# R7KA8P1AD register map
Vendor: Renesas Electronics Corporation; Series: RA8; File version: 1.10.02
CPU: CM85 r0p2, little endian, MPU, FPU, VTOR, 4 interrupt priority bits, 96 interrupts
Registers are 32-bit, read-write, reset 0x0 unless marked. A register's access mark holds for its fields unless they carry their own. Offsets are from the block's base; [hi:lo] are bit positions; {n}, {i} and the like mark numbered series; 'fields as' and 'values as' point back to an identical list.

## MIPI_DSI
Base 0x40346000
Same registers: MIPI_DSI_NS 0x50346000
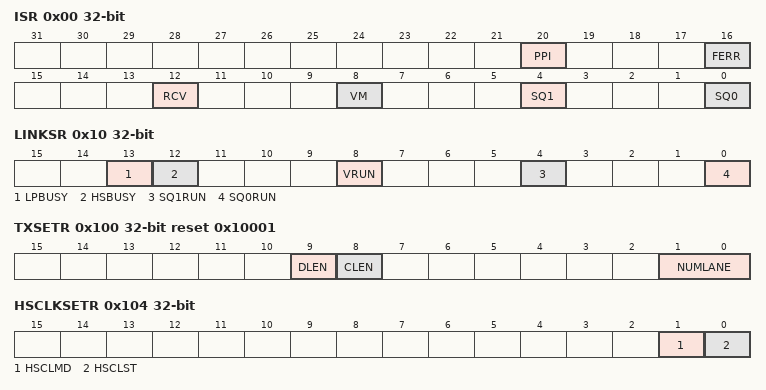
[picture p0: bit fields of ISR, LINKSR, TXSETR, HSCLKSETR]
0x00 ISR ro — Interrupt Status Register
  [20] PPI — PPI Interrupt Flag
    0=No interrupt detected; 1=PPI interrupt detected
  [16] FERR — Fatal Error Interrupt Flag
    0=No interrupt detected; 1=Fatal Error interrupt detected
  [12] RCV — Receive Interrupt Flag
    0=No interrupt detected; 1=Receive interrupt detected
  [8] VM — Video Mode Interrupt Flag
    0=No interrupt detected; 1=Video Mode interrupt detected
  [4] SQ1 — Sequence Channel-1 Interrupt Flag
    0=No interrupt detected; 1=Sequence Operation Channel-1 interrupt detected
  [0] SQ0 — Sequence Channel-0 Interrupt Flag
    0=No interrupt detected; 1=Sequence Operation Channel-0 interrupt detected
0x10 LINKSR ro — Link Status Register
  [13] LPBUSY — LP Operation Busy Flag
    0=LP mode stopped; 1=LP mode in operation
  [12] HSBUSY — HS Operation Busy Flag
    0=HS mode stopped; 1=HS mode in operation
  [8] VRUN — Video Mode Operation Running Flag
    0=Video mode stopped; 1=Video mode in operation
  [4] SQ1RUN — Sequence Channel-1 Running Flag
    0=Sequence Operation Channel-1 stopped; 1=Sequence Operation Channel-1 in operation
  [0] SQ0RUN — Sequence Channel-0 Running Flag
    0=Sequence Operation Channel-0 stopped; 1=Sequence Operation Channel-0 in operation
0x100 TXSETR reset 0x10001 — Transmit Set Register
  [9] DLEN — Data Lane Enable
    0=Disable; 1=Enable
  [8] CLEN — Clock Lane Enable
    0=Disable; 1=Enable
  [1:0] NUMLANE — Number of Lane
    0=1 Lane (Use of Lane-0); 1=2 Lane (Use of Lane-0 and Lane-1); other=Others (Setting prohibited)
0x104 HSCLKSETR — HS Clock Set Register
  [1] HSCLMD — HS Clock Running Mode
    0=Non-continuous clock mode; 1=Continuous clock mode
  [0] HSCLST — HS Clock Start
    0=Stop HS transmission (keep LP state); 1=Start HS transmission
0x108 ULPSSETR reset 0xA0 — ULPS Set Register
  [7:0] WKUP — ULPS Wakeup Period
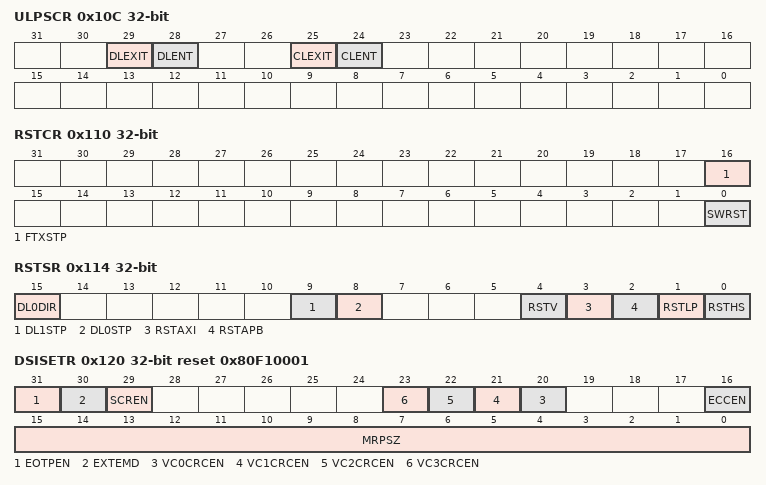
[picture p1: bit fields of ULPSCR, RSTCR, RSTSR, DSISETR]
0x10C ULPSCR wo — ULPS Control Register
  [29] DLEXIT — DL ULPS Exit
    0=No operation; 1=Data Lanes exit from ULPS
  [28] DLENT — DL ULPS Enter
    0=No operation; 1=Transition Data Lanes to ULPS
  [25] CLEXIT — CL ULPS Exit
    0=No operation; 1=Clock Lane exits from ULPS
  [24] CLENT — CL ULPS Enter
    0=No operation; 1=Transition Clock Lane to ULPS
0x110 RSTCR — Reset Control Register
  [16] FTXSTP — Force TX Stop Mode
    0=Finish the Force Stop state; 1=Force data lanes into transmit mode and generate Stop state
  [0] SWRST — Software Reset
    0=Complete the software reset; 1=Request a software reset
0x114 RSTSR ro — Reset Status Register
  [15] DL0DIR — Data Lane-0 Direction
    0=TX mode; 1=RX mode
  [9] DL1STP — Data Lane-1 Stop Status
    0=Not Stop state; 1=Stop state
  [8] DL0STP — Data Lane-0 Stop Status
    0=Not Stop state; 1=Stop state
  [4] RSTV — Video Software Reset Status
    0=Not in software reset procedure; 1=Running software reset procedure for Video mode
  [3] RSTAXI — AXI Software Reset Status
    0=Not in software reset procedure; 1=Running software reset procedure for AXI bus
  [2] RSTAPB — APB Software Reset Status
    0=Not in software reset procedure; 1=Running software reset procedure for APB bus
  [1] RSTLP — LP Software Reset Status
    0=Not in software reset procedure; 1=Running software reset procedure for LP mode
  [0] RSTHS — HS Software Reset Status
    0=Not in software reset procedure; 1=Running software reset procedure for HS mode
0x120 DSISETR reset 0x80F10001 — DSI Set Register
  [31] EOTPEN — HS Transfer EoTp Enable
    0=Disable; 1=Enable
  [30] EXTEMD — External Tearing Effect Detection Sense Select
    0=Rising edge; 1=Falling edge
  [29] SCREN — Data Scramble Enable
    0=Disable; 1=Enable
  [n+20] VC{n}CRCEN (n=0..3) — VC-{n} CRC Check Enable
    0=Disable; 1=Enable
  [16] ECCEN — ECC Check Enable
    0=Disable; 1=Enable
  [15:0] MRPSZ — Maximum Return Packet Size
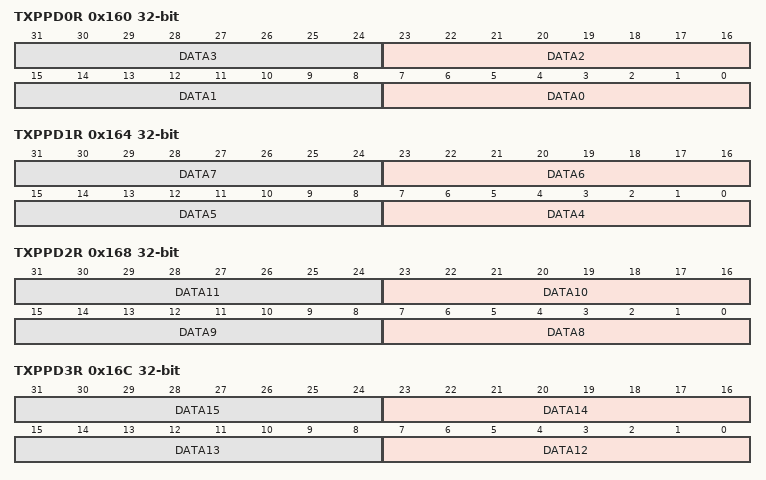
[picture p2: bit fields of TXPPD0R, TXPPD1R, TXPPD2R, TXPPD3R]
0x160 TXPPD0R — Transmit Packet Payload Data 0 Register
  [8n+7:8n] DATA{n} (n=0..3) — Payload Data {n}
0x164 TXPPD1R — Transmit Packet Payload Data 1 Register
  [8n-25:8n-32] DATA{n} (n=4..7) — Payload Data {n}
0x168 TXPPD2R — Transmit Packet Payload Data 2 Register
  [8n-57:8n-64] DATA{n} (n=8..11) — Payload Data {n}
0x16C TXPPD3R — Transmit Packet Payload Data 3 Register
  [8n-89:8n-96] DATA{n} (n=12..15) — Payload Data {n}
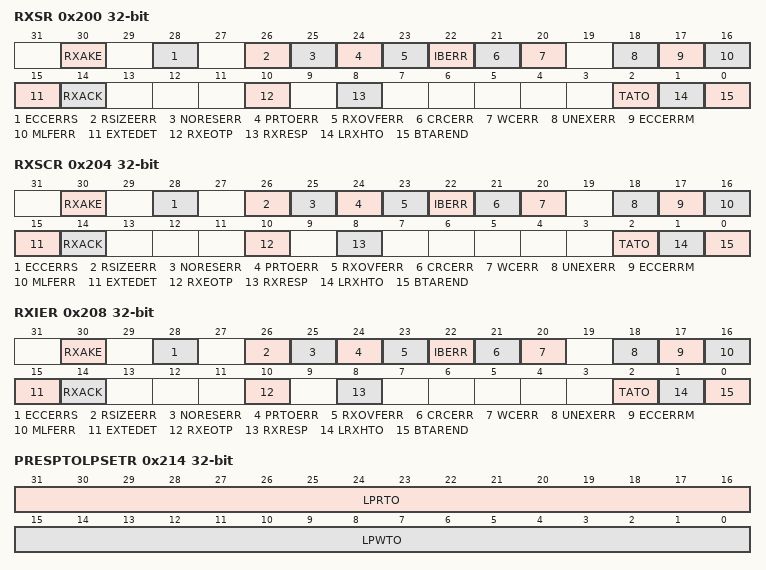
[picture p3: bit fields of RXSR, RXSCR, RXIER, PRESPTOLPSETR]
0x200 RXSR ro — Receive Status Register
  [30] RXAKE — Acknowledge and Error Report Receive Interrupt Flag
    0=No received; 1=An acknowledge and error report packet received
  [28] ECCERRS — Single Bit ECC Error Interrupt Flag
    0=No error detected; 1=A single-bit ECC error detected
  [26] RSIZEERR — Return Packet Size Error Interrupt Flag
    0=No error detected; 1=Oversize error in a received long packet detected
  [25] NORESERR — No Response Error Interrupt Flag
    0=No error occurred; 1=No triggers or packets returned during BTA period
  [24] PRTOERR — Peripheral Response Timeout Error Interrupt Flag
    0=No error occurred; 1=Peripheral response timeout occurred
  [23] RXOVFERR — Receive Buffer Overflow Error Interrupt Flag
    0=No error detected; 1=A buffer overflow error detected on receiving long packets
  [22] IBERR — Internal Bus Error Interrupt Flag
    0=No error detected; 1=Internal AXI bus write failed
  [21] CRCERR — CRC Error Interrupt Flag
    0=No error detected; 1=CRC error detected
  [20] WCERR — Word Count Error Interrupt Flag
    0=No error detected; 1=The length of the received packet is shorter than the Word Count (WC) indicated in the packet header
  [18] UNEXERR — Unexpected Packet Error Interrupt Flag
    0=No error; 1=Unexpected packet received
  [17] ECCERRM — Multi Bit ECC Error Interrupt Flag
    0=No error detected; 1=A multi-bit ECC error detected
  [16] MLFERR — Malform Error Interrupt Flag
    0=No error received; 1=A packet of less than 4 bytes received
  [15] EXTEDET — External Tearing Effect Detect Interrupt Flag
    0=Not detected; 1=External tearing effect detected
  [14] RXACK — ACK Trigger Receive Interrupt Flag
    0=No trigger received; 1=ACK trigger received
  [10] RXEOTP — EoTp Receive Interrupt Flag
    0=No received; 1=EoTp received
  [8] RXRESP — Response Packet Receive Interrupt Flag
    0=No response received; 1=Response packet received
  [2] TATO — Turnaround Acknowledge Timeout Interrupt Flag
    0=Not detected; 1=Turnaround Acknowledge Timeout (TA_TO) detected
  [1] LRXHTO — LP-RX Host Processor Timeout Interrupt Flag
    0=Not detected; 1=LP-RX Host Processor Timeout (LRX-H_TO) detected
  [0] BTAREND — BTA Request End Interrupt Flag
    0=Not detected; 1=BTA completion detected
0x204 RXSCR wo — Receive Status Clear Register
  [30] RXAKE — Acknowledge and Error Report Receive Interrupt Flag Clear
    0=No operation; 1=Clear the RXSR.RXAKE flag
  [28] ECCERRS — Single Bit ECC Error Interrupt Flag Clear
    0=No operation; 1=Clear the RXSR.ECCERRS flag
  [26] RSIZEERR — Return Packet Size Error Interrupt Flag Clear
    0=No operation; 1=Clear the RXSR.RSIZEERR flag
  [25] NORESERR — No Response Error Interrupt Flag Clear
    0=No operation; 1=Clear the RXSR.NORESERR flag
  [24] PRTOERR — Peripheral Response Timeout Error Interrupt Flag Clear
    0=No operation; 1=Clear the RXSR.PRTOERR flag
  [23] RXOVFERR — Receive Buffer Overflow Error Interrupt Flag Clear
    0=No operation; 1=Clear the RXSR.RXOVFERR flag
  [22] IBERR — Internal Bus Error Interrupt Flag Clear
    0=No operation; 1=Clear the RXSR.IBERR flag
  [21] CRCERR — CRC Error Interrupt Flag Clear
    0=No operation; 1=Clear the RXSR.CRCERR flag
  [20] WCERR — Word Count Error Interrupt Flag Clear
    0=No operation; 1=Clear the RXSR.WCERR flag
  [18] UNEXERR — Unexpected Packet Error Interrupt Flag Clear
    0=No operation; 1=Clear the RXSR.UNEXERR flag
  [17] ECCERRM — Multi Bit ECC Error Interrupt Flag Clear
    0=No operation; 1=Clear the RXSR.ECCERRM flag
  [16] MLFERR — Malform Error Interrupt Flag Clear
    0=No operation; 1=Clear the RXSR.MLFERR flag
  [15] EXTEDET — External Tearing Effect Detect Interrupt Flag Clear
    0=No operation; 1=Clear the RXSR.EXTEDET flag
  [14] RXACK — ACK Trigger Receive Interrupt Flag Clear
    0=No operation; 1=Clear the RXSR.RXACK flag
  [10] RXEOTP — EoTp Receive Interrupt Flag Clear
    0=No operation; 1=Clear the RXSR.RXEOTP flag
  [8] RXRESP — Response Packet Receive Interrupt Flag Clear
    0=No operation; 1=Clear the RXSR.RXRESP flag
  [2] TATO — Turnaround Acknowledge Timeout Interrupt Flag Clear
    0=No operation; 1=Clear the RXSR.TATO flag
  [1] LRXHTO — LP-RX Host Processor Timeout Interrupt Flag Clear
    0=No operation; 1=Clear the RXSR.LRXHTO flag
  [0] BTAREND — BTA Request End Interrupt Flag Clear
    0=No operation; 1=Clear the RXSR.BTAREND flag
0x208 RXIER — Receive Interrupt Enable Register
  [all] fields
    0=Disable; 1=Enable
  [30] RXAKE — Acknowledge and Error Report Receive Interrupt Enable
  [28] ECCERRS — Single Bit ECC Error Interrupt Enable
  [26] RSIZEERR — Return Packet Size Error Interrupt Enable
  [25] NORESERR — No Response Error Interrupt Enable
  [24] PRTOERR — Peripheral Response Timeout Error Interrupt Enable
  [23] RXOVFERR — Receive Buffer Overflow Error Interrupt Enable
  [22] IBERR — Internal Bus Error Interrupt Enable
  [21] CRCERR — CRC Error Interrupt Enable
  [20] WCERR — Word Count Error Interrupt Enable
  [18] UNEXERR — Unexpected Packet Error Interrupt Enable
  [17] ECCERRM — Multi-bit ECC Error Interrupt Enable
  [16] MLFERR — Malform Error Interrupt Enable
  [15] EXTEDET — External Tearing Effect Detect Interrupt Enable
  [14] RXACK — ACK Trigger Receive Interrupt Enable
  [10] RXEOTP — EoTp Receive Interrupt Enable
  [8] RXRESP — Response Packet Receive Interrupt Enable
  [2] TATO — Turnaround Acknowledge Timeout Interrupt Enable
  [1] LRXHTO — LP-RX Host Processor Timeout Interrupt Enable
  [0] BTAREND — BTA Request End Interrupt Enable
0x210 PRESPTOBTASETR — Peripheral Response Timeout BTA Set Register
  [31:0] PRTBTA — Peripheral Response Timeout Count
0x214 PRESPTOLPSETR — Peripheral Response Timeout LP Set Register
  [31:16] LPRTO — LPDT READ Request Timeout
  [15:0] LPWTO — LPDT WRITE Request Timeout
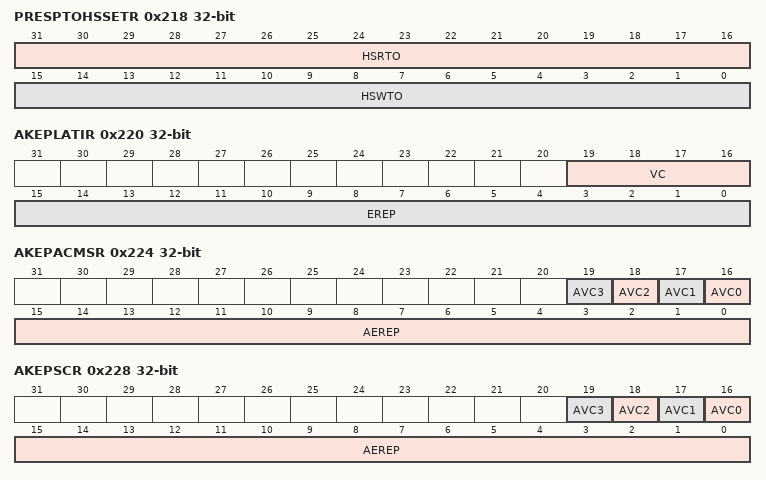
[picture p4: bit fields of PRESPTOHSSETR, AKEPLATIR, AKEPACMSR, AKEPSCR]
0x218 PRESPTOHSSETR — Peripheral Response Timeout HS Set Register
  [31:16] HSRTO — HS READ Request Timeout
  [15:0] HSWTO — HS WRITE Request Timeout
0x220 AKEPLATIR ro — Acknowledge and Error Report Packet Parameter Latest Info Register
  [19:16] VC — Virtual Channel ID
    0=No Error Report received; 1=From VC-0; 2=From VC-1; 4=From VC-2; 8=From VC-3; other=Others (Reserved)
  [15:0] EREP — Error Report
0x224 AKEPACMSR ro — Acknowledge and Error Report Packet Parameter Accumulate Status Register
  [n+16] AVC{n} (n=0..3) — Virtual Channel-{n} Accumulated Information
    0=No Error Report received from VC-{n}; 1=Received an Acknowledge and Error Report from VC-{n}
  [15:0] AEREP — Accumulated Error Report
0x228 AKEPSCR wo — Acknowledge and Error Report Packet Parameter Status Clear Register
  [n+16] AVC{n} (n=0..3) — Virtual Channel-{n} Accumulated Information Clear
    0=No operation; 1=Clear the AKEPACMSR.AVC{n} bit
  [15:0] AEREP — Accumulated Error Report Clear
    0=No operation; 1=Clear the AKEPACMSR.AEREP[15:0] bits
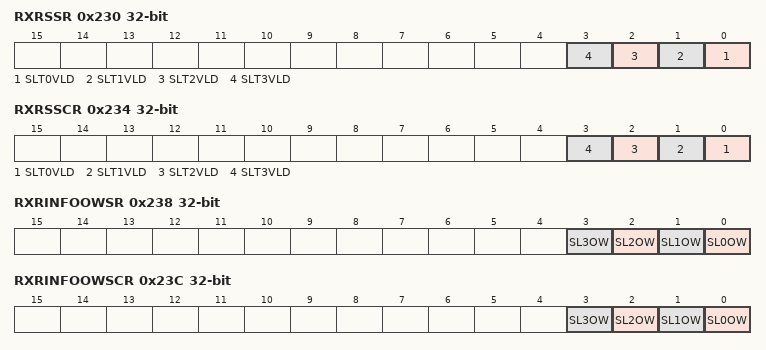
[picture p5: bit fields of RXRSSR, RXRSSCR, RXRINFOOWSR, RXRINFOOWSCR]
0x230 RXRSSR ro — Receive Result Saved Status Register
  [n] SLT{n}VLD (n=0..3) — Slot-{n} Valid Flag
    0=None received; 1=Response packet is received and stored in the RXRSS{n}R register
0x234 RXRSSCR wo — Receive Result Saved Status Clear Register
  [n] SLT{n}VLD (n=0..3) — Slot-{n} Valid Flag Clear
    0=No operation; 1=Clear the RXRSSR.SLT{n}VLD flag
0x238 RXRINFOOWSR ro — Receive Result Info Overwrite Status Register
  [n] SL{n}OW (n=0..3) — Slot-{n} Information Overwrite Flag
    0=No overwritten; 1=Slot-{n} information overwritten
0x23C RXRINFOOWSCR wo — Receive Result Info Overwrite Status Clear Register
  [n] SL{n}OW (n=0..3) — Slot-{n} Information Overwrite Flag Clear
    0=No operation; 1=Clear the RXRINFOOWSR.SL{n}OW flag
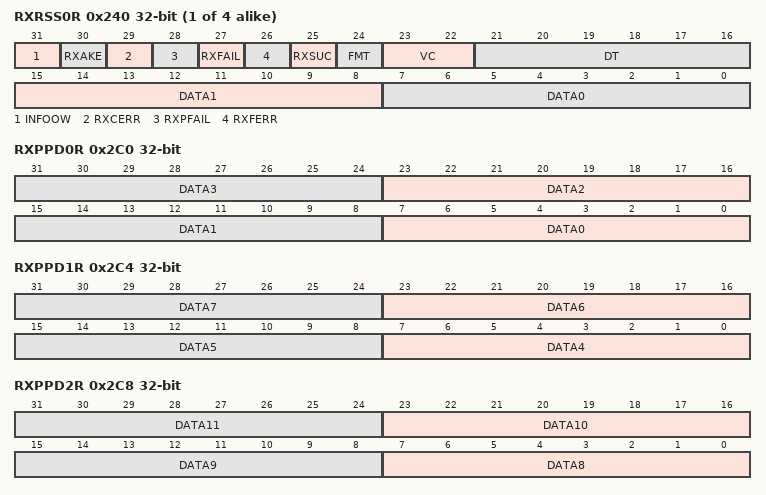
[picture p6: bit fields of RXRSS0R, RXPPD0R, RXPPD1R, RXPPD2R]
{0x240+4i} RXRSS{i}R (i=0..3) ro — Receive Result Save Slot-x Register (x = 0 to 3)
  [31] INFOOW — Information Overwrite
    0=No update; 1=This register information (RXRSSxR[30:0]) was overwritten
  [30] RXAKE — Receive Acknowledge and Error Report Packet
    0=No received; 1=An Acknowledge and Error Report packet received
  [29] RXCERR — Receive Correctable Error
    0=No error; 1=Correctable error detected
  [28] RXPFAIL — Receive Packet Data Fail
    0=No error; 1=Payload data not saved correctly
  [27] RXFAIL — Receive Fail
    0=No error; 1=Expected receive did not occur
  [26] RXFERR — Fatal Error
    0=No fatal error; 1=Fatal timeout occurred during BTA
  [25] RXSUC — Receive Success
    0=No received; 1=Response packet or ACK trigger received
  [24] FMT — Packet Format
    0=Short packet; 1=Long packet
  [23:22] VC — Virtual Channel ID
  [21:16] DT — Data Type
  [15:8] DATA1
  [7:0] DATA0
0x2C0 RXPPD0R ro — Receive Packet Payload Data 0 Register
  [8n+7:8n] DATA{n} (n=0..3) — Payload Data {n}
0x2C4 RXPPD1R ro — Receive Packet Payload Data 1 Register
  [8n-25:8n-32] DATA{n} (n=4..7) — Payload Data {n}
0x2C8 RXPPD2R ro — Receive Packet Payload Data 2 Register
  [8n-57:8n-64] DATA{n} (n=8..11) — Payload Data {n}
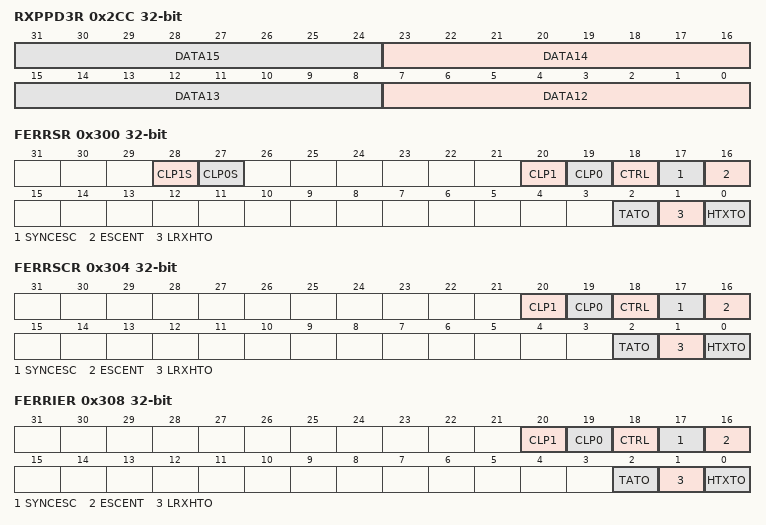
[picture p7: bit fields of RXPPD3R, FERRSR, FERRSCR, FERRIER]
0x2CC RXPPD3R ro — Receive Packet Payload Data 3 Register
  [8n-89:8n-96] DATA{n} (n=12..15) — Payload Data {n}
0x2E0 HSTXTOSETR — HS TX Timeout Set Register
  [31:0] HTXTO — HS TX Timeout Count
0x2E4 LRXHTOSETR — LRX-H Timeout Set Register
  [31:0] LRXHTO — LP-RX Host Processor Timeout
0x2E8 TATOSETR — TA Timeout Set Register
  [31:0] TATO — Turnaround Acknowledge Timeout
0x300 FERRSR ro — Fatal Error Status Register
  [28] CLP1S — LP1 Contention Error Status
    0=Normal state; 1=LP1 Contention Error (ErrContentionLP1) state
  [27] CLP0S — LP0 Contention Error Status
    0=Normal state; 1=LP0 Contention Error (ErrContentionLP0) state
  [20] CLP1 — LP1 Contention Error Interrupt Flag
    0=No error detected; 1=LP1 Contention Error (ErrContentionLP1) detected
  [19] CLP0 — LP0 Contention Error Interrupt Flag
    0=No error detected; 1=LP0 Contention Error (ErrContentionLP0) detected
  [18] CTRL — Control Error Interrupt Flag
    0=No error detected; 1=Control Error (ErrControl) detected
  [17] SYNCESC — LPDT Sync Error Interrupt Flag
    0=No error detected; 1=LPDT Synchronization Error (ErrSyncEsc) detected
  [16] ESCENT — Escape mode Entry Error Interrupt Flag
    0=No error detected; 1=Escape mode Entry Error (ErrEsc) detected
  [2] TATO — Turnaround Acknowledge Timeout Interrupt Flag
    values as RXSR.TATO
  [1] LRXHTO — LP-RX Host Processor Timeout Interrupt Flag
    values as RXSR.LRXHTO
  [0] HTXTO — HS TX Timeout Interrupt Flag
    0=Not detected; 1=HS TX Timeout (HTX_TO) detected
0x304 FERRSCR wo — Fatal Error Status Clear Register
  [20] CLP1 — LP1 Contention Error Interrupt Flag Clear
    0=No operation; 1=Clear the FERRSR.CLP1 flag
  [19] CLP0 — LP0 Contention Error Interrupt Flag Clear
    0=No operation; 1=Clear the FERRSR.CLP0 flag
  [18] CTRL — Control Error Interrupt Flag Clear
    0=No operation; 1=Clear the FERRSR.CTRL flag
  [17] SYNCESC — LPDT Sync Error Interrupt Flag Clear
    0=No operation; 1=Clear the FERRSR.SYNCESC flag
  [16] ESCENT — Escape Mode Entry Error Interrupt Flag Clear
    0=No operation; 1=Clear the FERRSR.ESCENT flag
  [2] TATO — Turnaround Acknowledge Timeout Interrupt Flag Clear
    0=No operation; 1=Clear the FERRSR.TATO flag
  [1] LRXHTO — LP-RX Host Processor Timeout Interrupt Flag Clear
    0=No operation; 1=Clear the FERRSR.LRXHTO flag
  [0] HTXTO — HS TX Timeout Interrupt Flag Clear
    0=No operation; 1=Clear the FERRSR.HTXTO flag
0x308 FERRIER — Fatal Error Interrupt Enable Register
  [all] fields
    0=Disable; 1=Enable
  [20] CLP1 — LP1 Contention Error Interrupt Enable
  [19] CLP0 — LP0 Contention Error Interrupt Enable
  [18] CTRL — Control Error Interrupt Enable
  [17] SYNCESC — LPDT Sync Error Interrupt Enable
  [16] ESCENT — Escape mode Entry Error Interrupt Enable
  [2] TATO — Turnaround Acknowledge Timeout Interrupt Enable
  [1] LRXHTO — LP-RX Host Processor Timeout Interrupt Enable
  [0] HTXTO — HS TX Timeout Interrupt Enable
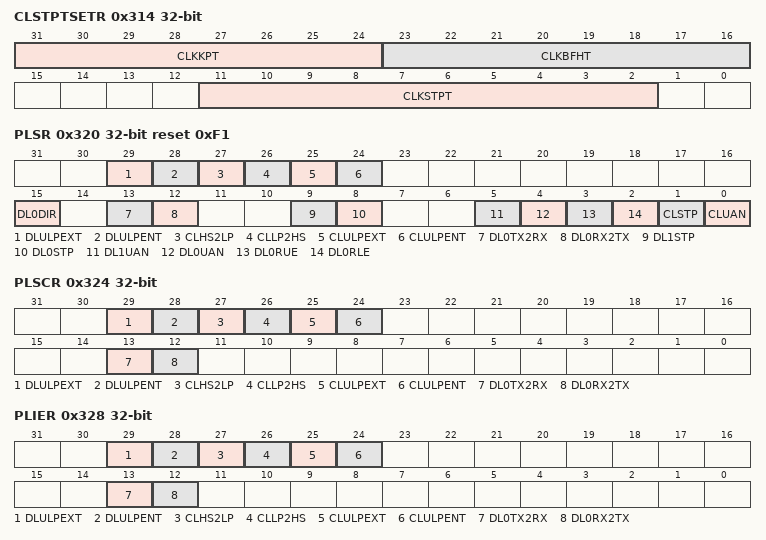
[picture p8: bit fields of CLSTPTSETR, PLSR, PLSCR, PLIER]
0x314 CLSTPTSETR — Clock Lane Stop Time Set Register
  [31:24] CLKKPT — Clock Keep Time
  [23:16] CLKBFHT — Clock Beforehand Time
  [11:2] CLKSTPT — Clock Stop Time
0x318 LPTRNSTSETR — LP Transition Time Set Register
  [9:0] GOLPBKT — Go LP and Back Time
0x320 PLSR ro reset 0xF1 — Physical Lane Status Register
  [29] DLULPEXT — Data Lane ULPS Exit Interrupt Flag
    0=Not detected; 1=Detected
  [28] DLULPENT — Data Lane ULPS Enter Interrupt Flag
    0=Not detected; 1=Detected
  [27] CLHS2LP — Clock Lane HS to LP Transition Interrupt Flag
    0=Not detected; 1=Detected
  [26] CLLP2HS — Clock Lane LP to HS Transition Interrupt Flag
    0=Not detected; 1=Detected
  [25] CLULPEXT — Clock Lane ULPS Exit Interrupt Flag
    0=Not detected; 1=Detected
  [24] CLULPENT — Clock Lane ULPS Enter Interrupt Flag
    0=Not detected; 1=Detected
  [15] DL0DIR — Data Lane-0 Direction
    0=Transmitter; 1=Receiver
  [13] DL0TX2RX — Data Lane-0 TX to RX Transition Interrupt Flag
    0=Not detected; 1=Detected
  [12] DL0RX2TX — Data Lane-0 RX to TX Transition Interrupt Flag
    0=Not detected; 1=Detected
  [9] DL1STP — Data Lane-1 Stop Status
    0=Not in Stop state; 1=In Stop state
  [8] DL0STP — Data Lane-0 Stop Status
    0=Not in Stop state; 1=In Stop state
  [5] DL1UAN — Data Lane-1 UlpsActiveNot Status
    0=In ULP state; 1=Not in ULP state
  [4] DL0UAN — Data Lane-0 UlpsActiveNot Status
    0=In ULP state; 1=Not in ULP state
  [3] DL0RUE — Data Lane-0 RxUlpsEsc Status
    0=Not in Escape Ultra-Low Power (Receive) mode; 1=In Escape Ultra-Low Power (Receive) mode
  [2] DL0RLE — Data Lane-0 RxLpdtEsc Status
    0=Not in Escape Low-Power Data Receive mode; 1=In Escape Low-Power Data Receive mode
  [1] CLSTP — Clock Lane Stop Status
    0=Not in Stop state; 1=In Stop state
  [0] CLUAN — Clock Lane UlpsActiveNot Status
    0=In ULP state; 1=Not in ULP state
0x324 PLSCR wo — Physical Lane Status Clear Register
  [29] DLULPEXT — Data Lane ULPS Exit Interrupt Flag Clear
    0=No operation; 1=Clear the PLSR.DLULPEXT flag
  [28] DLULPENT — Data Lane ULPS Enter Interrupt Flag Clear
    0=No operation; 1=Clear the PLSR.DLULPENT flag
  [27] CLHS2LP — Clock Lane HS to LP Transition Interrupt Flag Clear
    0=No operation; 1=Clear the PLSR.CLHS2LP flag
  [26] CLLP2HS — Clock Lane LP to HS Transition Interrupt Flag Clear
    0=No operation; 1=Clear the PLSR.CLLP2HS flag
  [25] CLULPEXT — Clock Lane ULPS Exit Interrupt Flag Clear
    0=No operation; 1=Clear the PLSR.CLULPEXT flag
  [24] CLULPENT — Clock Lane ULPS Enter Interrupt Flag Clear
    0=No operation; 1=Clear the PLSR.CLULPENT flag
  [13] DL0TX2RX — Data Lane-0 TX to RX Transition Interrupt Flag Clear
    0=No operation; 1=Clear the PLSR.DL0TX2RX flag
  [12] DL0RX2TX — Data Lane-0 RX to TX Transition Interrupt Flag Clear
    0=No operation; 1=Clear the PLSR.DL0RX2TX flag
0x328 PLIER — Physical Lane Interrupt Enable Register
  [all] fields
    0=Disable; 1=Enable
  [29] DLULPEXT — Data Lane ULPS Exit Interrupt Enable
  [28] DLULPENT — Data Lane ULPS Enter Interrupt Enable
  [27] CLHS2LP — Clock Lane HS to LP Transition Interrupt Enable
  [26] CLLP2HS — Clock Lane LP to HS Transition Interrupt Enable
  [25] CLULPEXT — Clock Lane ULPS Exit Interrupt Enable
  [24] CLULPENT — Clock Lane ULPS Enter Interrupt Enable
  [13] DL0TX2RX — Data Lane-0 TX to RX Transition Interrupt Enable
  [12] DL0RX2TX — Data Lane-0 RX to TX Transition Interrupt Enable
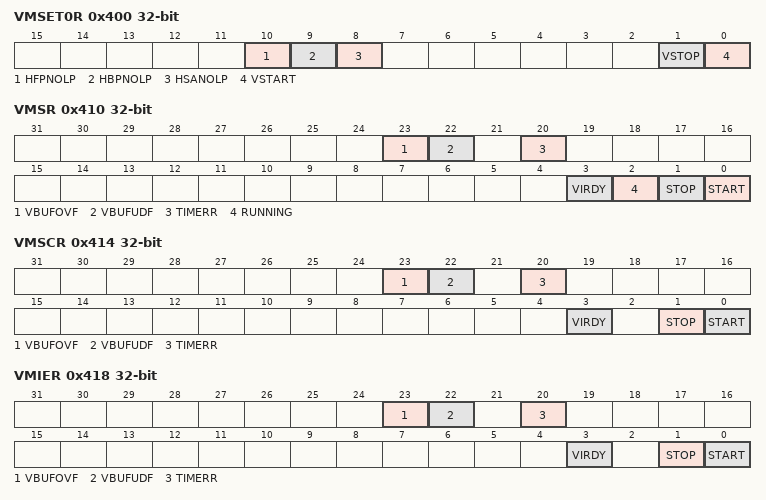
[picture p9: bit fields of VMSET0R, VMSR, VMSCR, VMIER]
0x400 VMSET0R — Video Mode Set 0 Register
  [10] HFPNOLP — HFP Period No LP
    0=Not suppressing the transition to LP during the HFP period; 1=Suppress the transition to LP during the HFP period and keep HS
  [9] HBPNOLP — HBP Period No LP
    0=Not suppressing the transition to LP during the HBP period; 1=Suppress the transition to LP during the HBP period and keep HS
  [8] HSANOLP — HSA Period No LP
    0=Not suppressing the transition to LP during the HSA period; 1=Suppress the transition to LP during the HSA period and keep HS
  [1] VSTOP wo — Video Mode Operation Stop
    0=No operation; 1=Stop Video mode operation
  [0] VSTART wo — Video Mode Operation Start
    0=No operation; 1=Start Video mode operation
0x404 VMSET1R reset 0x10530000 — Video Mode Set 1 Register
  [13:2] DLY — Delay Value
0x410 VMSR ro — Video Mode Status Register
  [23] VBUFOVF — Video Buffer Overflow Error Interrupt Flag
    0=Data overflow has not occurred; 1=Data overflow has occurred in the video buffer
  [22] VBUFUDF — Video Buffer Underflow Error Interrupt Flag
    0=Data underflow has not occurred; 1=Data underflow has occurred in the video buffer
  [20] TIMERR — Timing Error Interrupt Flag
    0=Timing error has not occurred; 1=Timing error has occurred during the Video mode operation
  [3] VIRDY — Video Mode Operation Ready Interrupt Flag
    0=Video mode operation is not ready; 1=Video mode operation is ready
  [2] RUNNING — Video Mode Operation Running Status
    0=Video mode operation is stopped; 1=Video mode operation is running
  [1] STOP — Video Mode Operation Stop Interrupt Flag
    0=Video mode operation has not stopped; 1=Video mode operation has stopped
  [0] START — Video Mode Operation Start Interrupt Flag
    0=Video mode operation has not started; 1=Video mode operation has started
0x414 VMSCR wo — Video Mode Status Clear Register
  [23] VBUFOVF — Video Buffer Overflow Error Interrupt Flag Clear
    0=No operation; 1=Clear the VMSR.VBUFOVF flag
  [22] VBUFUDF — Video Buffer Underflow Error Interrupt Flag Clear
    0=No operation; 1=Clear the VMSR.VBUFUDF flag
  [20] TIMERR — Timing Error Interrupt Flag Clear
    0=No operation; 1=Clear the VMSR.TIMERR flag
  [3] VIRDY — Video Mode Operation Ready Interrupt Flag Clear
    0=No operation; 1=Clear the VMSR.VIRDY flag
  [1] STOP — Video Mode Operation Stop Interrupt Flag Clear
    0=No operation; 1=Clear the VMSR.STOP flag
  [0] START — Video Mode Operation Start Interrupt Flag Clear
    0=No operation; 1=Clear the VMSR.START flag
0x418 VMIER — Video Mode Interrupt Enable Register
  [all] fields
    0=Disable; 1=Enable
  [23] VBUFOVF — Video Buffer Overflow Error Interrupt Enable
  [22] VBUFUDF — Video Buffer Underflow Error Interrupt Enable
  [20] TIMERR — Timing Error Interrupt Enable
  [3] VIRDY — Video Mode Operation Ready Interrupt Enable
  [1] STOP — Video Mode Operation Stop Interrupt Enable
  [0] START — Video Mode Operation Start Interrupt Enable
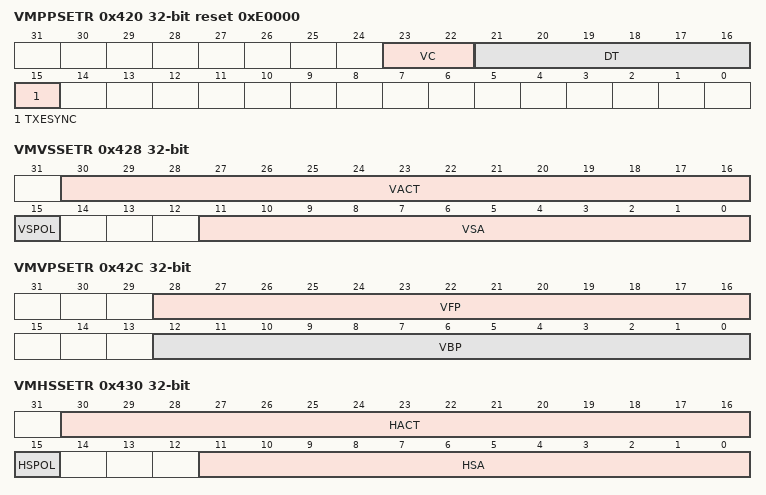
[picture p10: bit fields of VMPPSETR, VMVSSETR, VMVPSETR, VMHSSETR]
0x420 VMPPSETR reset 0xE0000 — Video Mode Pixel Packet Set Register
  [23:22] VC — Video Mode Virtual Channel
  [21:16] DT — Video Mode Data Type
    14=Packed Pixel Stream, 16-bit RGB; 30=Packed Pixel Stream, 18-bit RGB; 62=Packed Pixel Stream, 24-bit RGB; other=Others (Setting prohibited)
  [15] TXESYNC — Transmit End of Sync Pulse
    0=HSE and VSE are not transmitted; 1=HSE and VSE are transmitted
0x428 VMVSSETR — Video Mode Vertical Size Set Register
  [30:16] VACT — Vertical Active Lines
  [15] VSPOL — VSYNC Polarity
    0=Active-high; 1=Active-low
  [11:0] VSA — VSA Lines
0x42C VMVPSETR — Video Mode Vertical Porch Set Register
  [28:16] VFP — VFP Lines
  [12:0] VBP — VBP Lines
0x430 VMHSSETR — Video Mode Horizontal Size Set Register
  [30:16] HACT — HACT Pixels
  [15] HSPOL — HSYNC Polarity
    0=Active-high; 1=Active-low
  [11:0] HSA — HSA Pixels
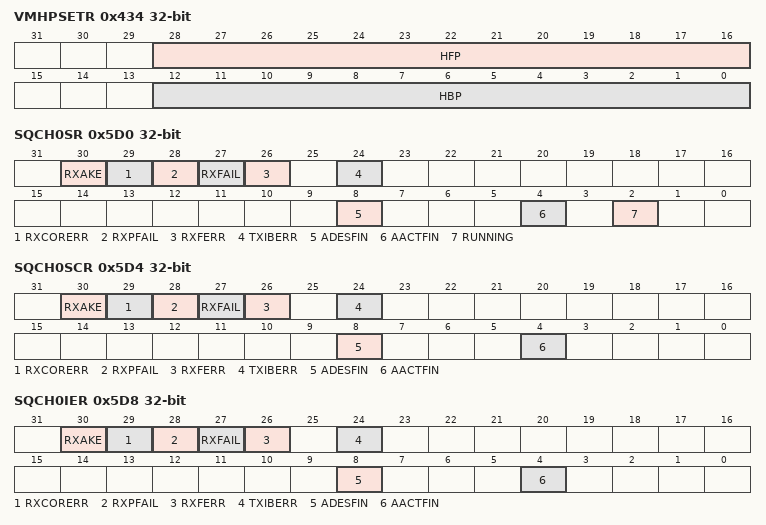
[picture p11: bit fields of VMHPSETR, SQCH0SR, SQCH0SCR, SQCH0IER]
0x434 VMHPSETR — Video Mode Horizontal Porch Set Register
  [28:16] HFP — HFP Pixels
  [12:0] HBP — HBP Pixels
0x5C0 SQCH0SET0R wo reset 0x800000 — Sequence Channel 0 Set 0 Register
  [0] START — Sequence Operation Start
    0=No operation; 1=Start the sequence operation
0x5D0 SQCH0SR ro — Sequence Channel 0 Status Register
  [30] RXAKE — Receive Acknowledge and Error Report Packet Interrupt Flag
    0=No error; 1=Acknowledge and Error Report Packet is received
  [29] RXCORERR — Receive Correctable Error Interrupt Flag
    0=No error; 1=Received packets have a correctable error
  [28] RXPFAIL — Receive Packet Data Fail Interrupt Flag
    0=No error; 1=Received packet data is not stored correctly
  [27] RXFAIL — Receive Fail Interrupt Flag
    0=No error; 1=Expected receive did not take place
  [26] RXFERR — Receive Fatal Error Interrupt Flag
    0=No error; 1=Fatal timeout occurred during BTA
  [24] TXIBERR — TX Internal Bus Error Interrupt Flag
    0=No error; 1=Internal AXI bus read error occurred
  [8] ADESFIN — All Descriptors Finish Interrupt Flag
    0=All descriptors have not finished; 1=All descriptors finished operations
  [4] AACTFIN — All Actions Finish Interrupt Flag
    0=All actions of a descriptor have not finished; 1=All actions of a descriptor finished operations
  [2] RUNNING — Sequence Operation Running Status
    0=Sequence operation is stopped; 1=Sequence operation is running
0x5D4 SQCH0SCR wo — Sequence Channel 0 Status Clear Register
  [30] RXAKE — Receive Acknowledge and Error Report Packet Interrupt Flag Clear
    0=No operation; 1=Clear the SQCH0SR.RXAKE flag
  [29] RXCORERR — Receive Correctable Error Interrupt Flag Clear
    0=No operation; 1=Clear the SQCH0SR.RXCORERR flag
  [28] RXPFAIL — Receive Packet Data Fail Interrupt Flag Clear
    0=No operation; 1=Clear the SQCH0SR.RXPFAIL flag
  [27] RXFAIL — Receive Fail Interrupt Flag Clear
    0=No operation; 1=Clear the SQCH0SR.RXFAIL flag
  [26] RXFERR — Receive Fatal Error Interrupt Flag Clear
    0=No operation; 1=Clear the SQCH0SR.RXFERR flag
  [24] TXIBERR — TX Internal Bus Error Interrupt Flag Clear
    0=No operation; 1=Clear the SQCH0SR.TXIBERR flag
  [8] ADESFIN — All Descriptors Finish Interrupt Flag Clear
    0=No operation; 1=Clear the SQCH0SR.ADESFIN flag
  [4] AACTFIN — All Actions Finish Interrupt Flag Clear
    0=No operation; 1=Clear the SQCH0SR.AACTFIN flag
0x5D8 SQCH0IER — Sequence Channel 0 Interrupt Enable Register
  [all] fields
    0=Disable; 1=Enable
  [30] RXAKE — Receive Acknowledge and Error Report Packet Interrupt Enable
  [29] RXCORERR — Receive Correctable Error Interrupt Enable
  [28] RXPFAIL — Receive Packet Data Fail Interrupt Enable
  [27] RXFAIL — Receive Fail Interrupt Enable
  [26] RXFERR — Receive Fatal Error Interrupt Enable
  [24] TXIBERR — TX Internal Bus Error Interrupt Enable
  [8] ADESFIN — All Descriptors Finish Interrupt Enable
  [4] AACTFIN — All Actions Finish Interrupt Enable
0x600 SQCH1SET0R wo reset 0x800000 — Sequence Channel 1 Set 0 Register
  fields as SQCH0SET0R
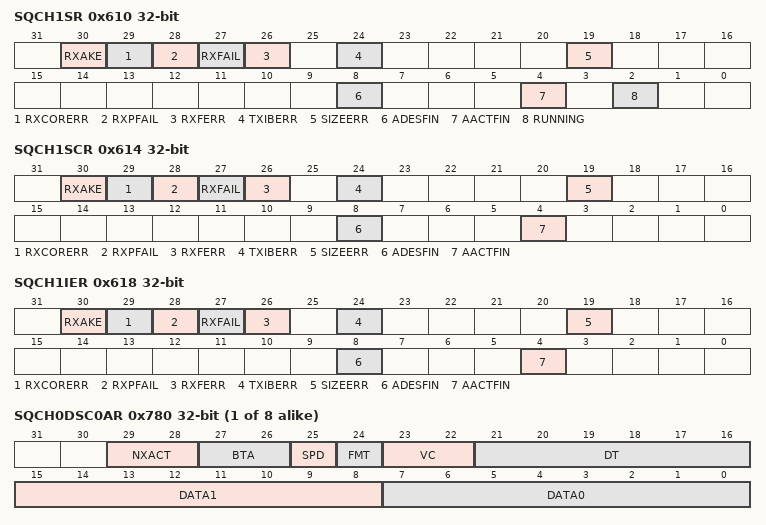
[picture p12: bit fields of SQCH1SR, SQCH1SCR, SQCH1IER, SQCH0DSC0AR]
0x610 SQCH1SR ro — Sequence Channel 1 Status Register
  [30] RXAKE — Receive Acknowledge and Error Report Packet Interrupt Flag
    values as SQCH0SR.RXAKE
  [29] RXCORERR — Receive Correctable Error Interrupt Flag
    0=No error; 1=Received packets have correctable error
  [28] RXPFAIL — Receive Packet Data Fail Interrupt Flag
    0=No error; 1=Received packet data is not stored correctly
  [27] RXFAIL — Receive Fail Interrupt Flag
    0=No error; 1=Expected receive did not take place
  [26] RXFERR — Receive Fatal Error Interrupt Flag
    0=No error; 1=Fatal timeout occurred during BTA
  [24] TXIBERR — TX Internal Bus Error Interrupt Flag
    0=No error; 1=Internal AXI bus read error occurred
  [19] SIZEERR — Packet Size Error Interrupt Flag
    0=No error; 1=Sequence packet size is too large
  [8] ADESFIN — All Descriptors Finish Interrupt Flag
    values as SQCH0SR.ADESFIN
  [4] AACTFIN — All Actions Finish Interrupt Flag
    values as SQCH0SR.AACTFIN
  [2] RUNNING — Sequence Operation Running Status
    values as SQCH0SR.RUNNING
0x614 SQCH1SCR wo — Sequence Channel 1 Status Clear Register
  [30] RXAKE — Receive Acknowledge and Error Report Packet Interrupt Flag Clear
    0=No operation; 1=Clear the SQCH1SR.RXAKE flag
  [29] RXCORERR — Receive Correctable Error Interrupt Flag Clear
    0=No operation; 1=Clear the SQCH1SR.RXCORERR flag
  [28] RXPFAIL — Receive Packet Data Fail Interrupt Flag Clear
    0=No operation; 1=Clear the SQCH1SR.RXPFAIL flag
  [27] RXFAIL — Receive Fail Interrupt Flag Clear
    0=No operation; 1=Clear the SQCH1SR.RXFAIL flag
  [26] RXFERR — Receive Fatal Error Interrupt Flag Clear
    0=No operation; 1=Clear the SQCH1SR.RXFERR flag
  [24] TXIBERR — TX Internal Bus Error Interrupt Flag Clear
    0=No operation; 1=Clear the SQCH1SR.TXIBERR flag
  [19] SIZEERR — Packet Size Error Interrupt Flag Clear
    0=No operation; 1=Clear the SQCH1SR.SIZEERR flag
  [8] ADESFIN — All Descriptors Finish Interrupt Flag Clear
    0=No operation; 1=Clear the SQCH1SR.ADESFIN flag
  [4] AACTFIN — All Actions Finish Interrupt Flag Clear
    0=No operation; 1=Clear the SQCH1SR.AACTFIN flag
0x618 SQCH1IER — Sequence Channel 1 Interrupt Enable Register
  [all] fields
    0=Disable; 1=Enable
  [30] RXAKE — Receive Acknowledge and Error Report Packet Interrupt Enable
  [29] RXCORERR — Receive Correctable Error Interrupt Enable
  [28] RXPFAIL — Receive Packet Data Fail Interrupt Enable
  [27] RXFAIL — Receive Fail Interrupt Enable
  [26] RXFERR — Receive Fatal Error Interrupt Enable
  [24] TXIBERR — TX Internal Bus Error Interrupt Enable
  [19] SIZEERR — Packet Size Error Interrupt Enable
  [8] ADESFIN — All Descriptors Finish Interrupt Enable
  [4] AACTFIN — All Actions Finish Interrupt Enable
{0x780+0x10*i} SQCH0DSC{i}AR (i=0..7) reset not defined — Sequence Channel 0 Descriptor-m A Register (m = 0 to 7)
  [29:28] NXACT — Next Action
    0=Terminate the sequence operation after this descriptor processing is finished; 1=Start the next descriptor processing after this descriptor processing is finished; other=Others (Settings prohibited)
  [27:26] BTA — Bus Turn Around
    0=TX request without BTA or no-operation; 1=TX non-read request with BTA; 2=TX read request with BTA; 3=BTA only
  [25] SPD — Speed
    0=High-speed; 1=Low-power
  [24] FMT — Format
    0=Short Packet; 1=Long Packet
  [23:22] VC — Virtual Channel
  [21:16] DT — Data Type
  [15:8] DATA1
  [7:0] DATA0
{0x784+0x10*i} SQCH0DSC{i}BR (i=0..7) reset not defined — Sequence Channel 0 Descriptor-m B Register (m = 0 to 7)
  [25:24] DTSEL — Data Select
    0=Use Packet Payload Data Register (TXPPDxR, RXPPDxR); 1=Use memory space; other=Others (Setting prohibited)
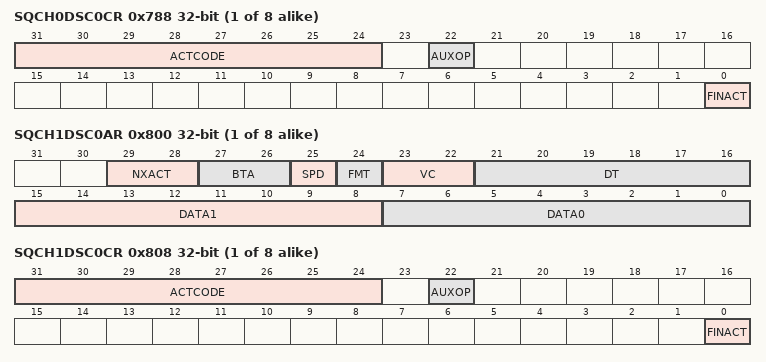
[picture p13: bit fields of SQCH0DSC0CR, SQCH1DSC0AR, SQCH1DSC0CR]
{0x788+0x10*i} SQCH0DSC{i}CR (i=0..7) reset not defined — Sequence Channel 0 Descriptor-m C Register
  [31:24] ACTCODE — Action Code
  [22] AUXOP — Auxiliary Operation
    0=Not using auxiliary operation; 1=Executing auxiliary operation
  [0] FINACT — Finish Action
    0=Disable; 1=Enable
{0x78C+0x10*i} SQCH0DSC{i}DR (i=0..7) reset not defined — Sequence Channel 0 Descriptor-m D Register (m = 0 to 7)
  [31:0] LADDR — Lower Address
{0x800+0x10*i} SQCH1DSC{i}AR (i=0..7) reset not defined — Sequence Channel 1 Descriptor-m A Register (m = 0 to 7)
  fields as SQCH0DSC0AR
{0x804+0x10*i} SQCH1DSC{i}BR (i=0..7) reset not defined — Sequence Channel 1 Descriptor-m B Register (m = 0 to 7)
  fields as SQCH0DSC0BR
{0x808+0x10*i} SQCH1DSC{i}CR (i=0..7) reset not defined — Sequence Channel 1 Descriptor-m C Register
  fields as SQCH0DSC0CR
{0x80C+0x10*i} SQCH1DSC{i}DR (i=0..7) reset not defined — Sequence Channel 1 Descriptor-m D Register (m = 0 to 7)
  [31:0] LADDR — Lower Address
